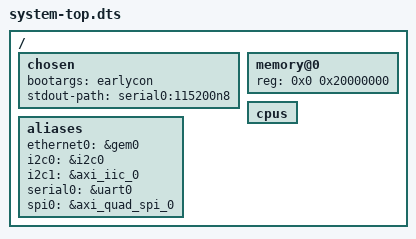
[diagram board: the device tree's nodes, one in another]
/*
 * CAUTION: This file is automatically generated by Xilinx.
 * Version: XSCT 
 * Today is: Tue Jul 29 21:42:08 2025
 */


/dts-v1/;
#include "zynq-7000.dtsi"
#include "pl.dtsi"
#include "pcw.dtsi"
/ {
	chosen {
		bootargs = "earlycon";
		stdout-path = "serial0:115200n8";
	};
	aliases {
		ethernet0 = &gem0;
		i2c0 = &i2c0;
		i2c1 = &axi_iic_0;
		serial0 = &uart0;
		spi0 = &axi_quad_spi_0;
	};
	memory@0 {
		device_type = "memory";
		reg = <0x0 0x20000000>;
	};
	cpus {
		/delete-node/ cpu@1 ;
	};
};
#include "system-user.dtsi"
